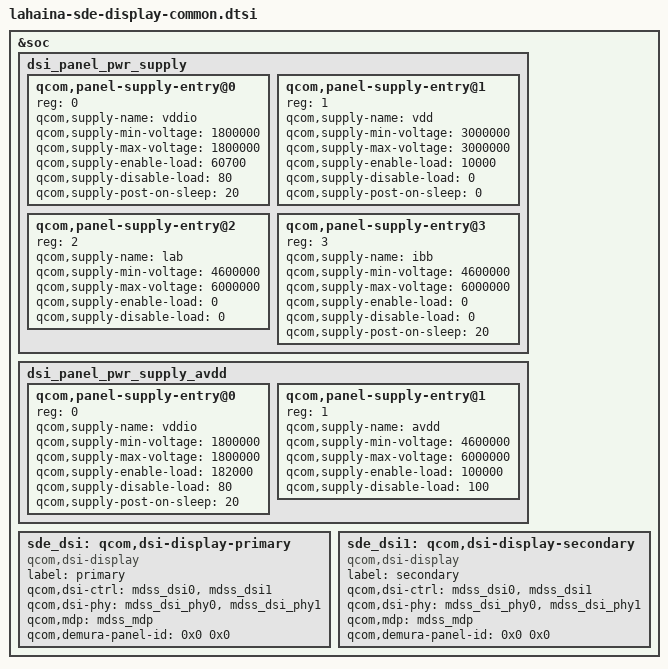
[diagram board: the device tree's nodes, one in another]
#include <dt-bindings/clock/mdss-5nm-pll-clk.h>

&soc {
	dsi_panel_pwr_supply: dsi_panel_pwr_supply {
		#address-cells = <1>;
		#size-cells = <0>;

		qcom,panel-supply-entry@0 {
			reg = <0>;
			qcom,supply-name = "vddio";
			qcom,supply-min-voltage = <1800000>;
			qcom,supply-max-voltage = <1800000>;
			qcom,supply-enable-load = <60700>;
			qcom,supply-disable-load = <80>;
			qcom,supply-post-on-sleep = <20>;
		};

		qcom,panel-supply-entry@1 {
			reg = <1>;
			qcom,supply-name = "vdd";
			qcom,supply-min-voltage = <3000000>;
			qcom,supply-max-voltage = <3000000>;
			qcom,supply-enable-load = <10000>;
			qcom,supply-disable-load = <0>;
			qcom,supply-post-on-sleep = <0>;
		};

		qcom,panel-supply-entry@2 {
			reg = <2>;
			qcom,supply-name = "lab";
			qcom,supply-min-voltage = <4600000>;
			qcom,supply-max-voltage = <6000000>;
			qcom,supply-enable-load = <0>;
			qcom,supply-disable-load = <0>;
		};

		qcom,panel-supply-entry@3 {
			reg = <3>;
			qcom,supply-name = "ibb";
			qcom,supply-min-voltage = <4600000>;
			qcom,supply-max-voltage = <6000000>;
			qcom,supply-enable-load = <0>;
			qcom,supply-disable-load = <0>;
			qcom,supply-post-on-sleep = <20>;
		};
	};

	dsi_panel_pwr_supply_avdd: dsi_panel_pwr_supply_avdd {
		#address-cells = <1>;
		#size-cells = <0>;

		qcom,panel-supply-entry@0 {
			reg = <0>;
			qcom,supply-name = "vddio";
			qcom,supply-min-voltage = <1800000>;
			qcom,supply-max-voltage = <1800000>;
			qcom,supply-enable-load = <182000>;
			qcom,supply-disable-load = <80>;
			qcom,supply-post-on-sleep = <20>;
		};

		qcom,panel-supply-entry@1 {
			reg = <1>;
			qcom,supply-name = "avdd";
			qcom,supply-min-voltage = <4600000>;
			qcom,supply-max-voltage = <6000000>;
			qcom,supply-enable-load = <100000>;
			qcom,supply-disable-load = <100>;
		};
	};

	sde_dsi: qcom,dsi-display-primary {
		compatible = "qcom,dsi-display";
		label = "primary";

		qcom,dsi-ctrl = <&mdss_dsi0 &mdss_dsi1>;
		qcom,dsi-phy = <&mdss_dsi_phy0 &mdss_dsi_phy1>;

		qcom,mdp = <&mdss_mdp>;
		qcom,demura-panel-id = <0x0 0x0>;
	};

	sde_dsi1: qcom,dsi-display-secondary {
		compatible = "qcom,dsi-display";
		label = "secondary";

		qcom,dsi-ctrl = <&mdss_dsi0 &mdss_dsi1>;
		qcom,dsi-phy = <&mdss_dsi_phy0 &mdss_dsi_phy1>;
		qcom,mdp = <&mdss_mdp>;
		qcom,demura-panel-id = <0x0 0x0>;
	};
};

